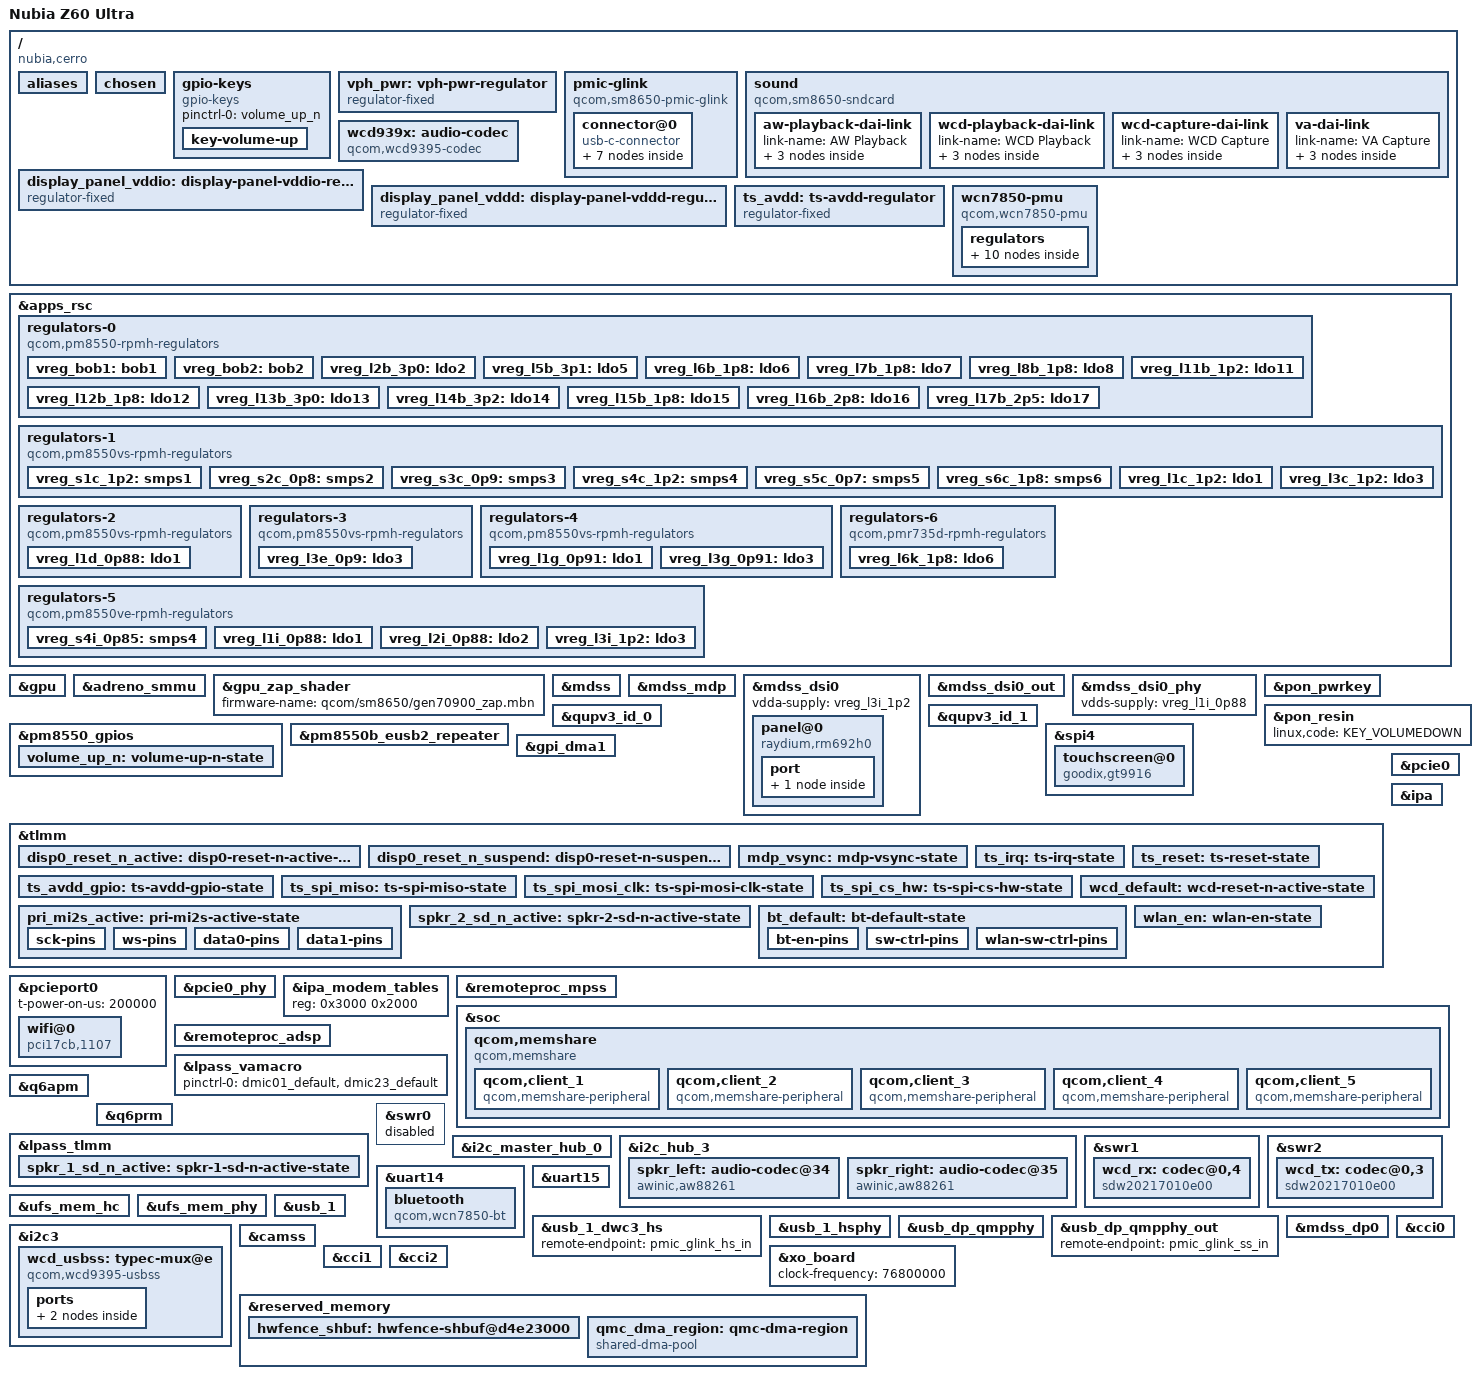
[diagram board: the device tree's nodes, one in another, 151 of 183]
// SPDX-License-Identifier: BSD-3-Clause
/*
 * Nubia Z60 Ultra (cerro / NX721J) mainline device tree.
 *
 * Provenance of the hardware facts:
 *   - Extracted offline from the stock firmware dump
 *     (see ../notes/cerro-hardware.md, ../downstream-dt/dts/dtbo_1.dts).
 *   - Cross-checked against the upstream SM8650 QRD reference board
 *     (arch/arm64/boot/dts/qcom/sm8650-qrd.dts), which carries the
 *     *identical* Visionox VTDR6130 panel and Goodix Berlin touch on
 *     spi4 (reset gpio161 / irq gpio162), UFS and USB wiring. cerro's
 *     display/touch/storage path is therefore a 1:1 match with the QRD.
 *
 * Scope: this is a first bring-up tree (console + storage + USB +
 * display + touch). Nubia-specific extras that are not needed to boot
 * pmOS to a display are intentionally omitted and listed at the bottom.
 *
 * Copyright (c) 2023, Linaro Limited (QRD reference)
 * Copyright (c) 2026, Nubia Z60U mainline port
 */

/dts-v1/;

#include <dt-bindings/gpio/gpio.h>
#include <dt-bindings/input/input.h>
#include <dt-bindings/interrupt-controller/irq.h>
#include <dt-bindings/regulator/qcom,rpmh-regulator.h>
#include <dt-bindings/sound/qcom,q6dsp-lpass-ports.h>
#include "sm8650.dtsi"
#include "pm8550.dtsi"
#include "pm8550b.dtsi"
#define PMK8550VE_SID 8
#include "pm8550ve.dtsi"
#include "pm8550vs.dtsi"
#include "pmk8550.dtsi"
#include "pmr735d_a.dtsi"

/* Phone SKU: hwfence is at 0xd4e23000 (not QRD 0xe6440000). */
/delete-node/ &hwfence_shbuf;

/ {
	model = "Nubia Z60 Ultra";
	compatible = "nubia,cerro", "qcom,sm8650";
	chassis-type = "handset";

	aliases {
		serial0 = &uart15;
		serial1 = &uart14;
	};

	chosen {
		stdout-path = "serial0:115200n8";
		/*
		 * Stock ABL leaves /proc/cmdline empty for our boot.img, so
		 * boot.img --cmdline is ineffective. Put bring-up args here.
		 */
		bootargs = "ignore_loglevel pd_ignore_unused clk_ignore_unused fw_devlink=on deferred_probe_timeout=60 console=tty0 fbcon=font:TER16x32 plymouth.enable=0 systemd.mask=plymouth-start.service systemd.mask=plymouth-quit.service systemd.mask=plymouth-quit-wait.service systemd.mask=plymouth-read-write.service systemd.mask=plymouth-reboot.service systemd.crash_reboot=1 panic=10 cerro_dtb=disp-on-oldsetup";
	};

	gpio-keys {
		compatible = "gpio-keys";

		pinctrl-0 = <&volume_up_n>;
		pinctrl-names = "default";

		key-volume-up {
			label = "Volume Up";
			linux,code = <KEY_VOLUMEUP>;
			gpios = <&pm8550_gpios 6 GPIO_ACTIVE_LOW>;
			debounce-interval = <15>;
			linux,can-disable;
			wakeup-source;
		};
	};

	vph_pwr: vph-pwr-regulator {
		compatible = "regulator-fixed";

		regulator-name = "vph_pwr";
		regulator-min-microvolt = <3700000>;
		regulator-max-microvolt = <3700000>;

		regulator-always-on;
		regulator-boot-on;
	};

	/*
	 * Battery + USB-C policy live on ADSP charger_pd (PMIC_RTR_ADSP_APPS).
	 * Without this node qcom_battmgr never probes: no capacity, no charge
	 * notifications. Graph endpoints match SM8650 MTP; orientation gpio is
	 * left unset until the Cerro CC pin is confirmed.
	 */
	pmic-glink {
		compatible = "qcom,sm8650-pmic-glink",
			     "qcom,sm8550-pmic-glink",
			     "qcom,pmic-glink";
		#address-cells = <1>;
		#size-cells = <0>;

		connector@0 {
			compatible = "usb-c-connector";
			reg = <0>;
			power-role = "dual";
			data-role = "dual";

			ports {
				#address-cells = <1>;
				#size-cells = <0>;

				port@0 {
					reg = <0>;
					pmic_glink_hs_in: endpoint {
						remote-endpoint = <&usb_1_dwc3_hs>;
					};
				};

				port@1 {
					reg = <1>;
					pmic_glink_ss_in: endpoint {
						remote-endpoint = <&usb_dp_qmpphy_out>;
					};
				};

				port@2 {
					reg = <2>;
					pmic_glink_sbu: endpoint {
						remote-endpoint = <&wcd_usbss_sbu_mux>;
					};
				};
			};
		};
	};

	/*
	 * s5fr/s5fu audio: WCD939x headset + 2× AW88261 smart PA (Cerro SKU).
	 * AOSP/stock: wsa-macro status=disabled; speakers on i2c_hub_3 @34/@35
	 * (chipid 0x2113). WSA SoundWire path retired after s5fq.
	 * s5fu: pri MI2S / i2s0 (gpio126–129) → AW88261; tplg from LEMANS-EVK
	 * (PRIMARY_MI2S_RX). Headset FE in old QRD tplg temporarily displaced.
	 */
	sound {
		compatible = "qcom,sm8650-sndcard", "qcom,sm8450-sndcard";
		model = "SM8650-CERRO";
		pinctrl-0 = <&pri_mi2s_active>;
		pinctrl-names = "default";
		/*
		 * s5fw: Audioreach MI2S needs q6prm IBIT vote before APM_CMD_SET_CFG.
		 * sc8280xp enables this on PRIMARY_MI2S startup (sm8250-style 1.536 MHz).
		 */
		clocks = <&q6prmcc LPASS_CLK_ID_PRI_MI2S_IBIT LPASS_CLK_ATTRIBUTE_COUPLE_NO>;
		clock-names = "pri_mi2s_ibit";
		audio-routing = "IN1_HPHL", "HPHL_OUT",
				"IN2_HPHR", "HPHR_OUT",
				"AMIC1", "MIC BIAS1",
				"AMIC2", "MIC BIAS2",
				"AMIC3", "MIC BIAS3",
				"AMIC4", "MIC BIAS3",
				"AMIC5", "MIC BIAS4",
				"TX SWR_INPUT0", "ADC1_OUTPUT",
				"TX SWR_INPUT1", "ADC2_OUTPUT",
				"TX SWR_INPUT2", "ADC3_OUTPUT",
				"TX SWR_INPUT3", "ADC4_OUTPUT";

		/* Speakers: AOSP pri_mi2s / i2s0 → 2× AW88261 (lemans-evk pattern) */
		aw-playback-dai-link {
			link-name = "AW Playback";

			cpu {
				sound-dai = <&q6apmbedai PRIMARY_MI2S_RX>;
			};

			codec {
				sound-dai = <&spkr_left>, <&spkr_right>;
			};

			platform {
				sound-dai = <&q6apm>;
			};
		};

		wcd-playback-dai-link {
			link-name = "WCD Playback";

			cpu {
				sound-dai = <&q6apmbedai RX_CODEC_DMA_RX_0>;
			};

			codec {
				sound-dai = <&wcd939x 0>, <&swr1 0>, <&lpass_rxmacro 0>;
			};

			platform {
				sound-dai = <&q6apm>;
			};
		};

		wcd-capture-dai-link {
			link-name = "WCD Capture";

			cpu {
				sound-dai = <&q6apmbedai TX_CODEC_DMA_TX_3>;
			};

			codec {
				sound-dai = <&wcd939x 1>, <&swr2 0>, <&lpass_txmacro 0>;
			};

			platform {
				sound-dai = <&q6apm>;
			};
		};

		/*
		 * Handset mics: stock LPASS DMIC on gpio6/7 and gpio8/9
		 * (dtbo dmic01/dmic23). va_macro is already bound; without
		 * this pinctrl the clocks stay unmuxed. Dedicated VA DMA so
		 * it does not steal WCD Capture's TX_CODEC_DMA_TX_3.
		 * Topology still has to grow a VA_CODEC_DMA_TX_0 backend
		 * before this link records; current CERRO tplg only feeds
		 * MultiMedia2 from TERTIARY_MI2S_TX.
		 */
		va-dai-link {
			link-name = "VA Capture";

			cpu {
				sound-dai = <&q6apmbedai VA_CODEC_DMA_TX_0>;
			};

			codec {
				sound-dai = <&lpass_vamacro 0>;
			};

			platform {
				sound-dai = <&q6apm>;
			};
		};
	};

	wcd939x: audio-codec {
		compatible = "qcom,wcd9395-codec", "qcom,wcd9390-codec";

		pinctrl-0 = <&wcd_default>;
		pinctrl-names = "default";

		qcom,micbias1-microvolt = <1800000>;
		qcom,micbias2-microvolt = <1800000>;
		qcom,micbias3-microvolt = <1800000>;
		qcom,micbias4-microvolt = <1800000>;
		qcom,mbhc-buttons-vthreshold-microvolt = <75000 150000 237000 500000 500000 500000 500000 500000>;
		qcom,mbhc-headset-vthreshold-microvolt = <1700000>;
		qcom,mbhc-headphone-vthreshold-microvolt = <50000>;
		qcom,rx-device = <&wcd_rx>;
		qcom,tx-device = <&wcd_tx>;

		reset-gpios = <&tlmm 107 GPIO_ACTIVE_LOW>;

		vdd-buck-supply = <&vreg_l15b_1p8>;
		vdd-rxtx-supply = <&vreg_l15b_1p8>;
		vdd-io-supply = <&vreg_l15b_1p8>;
		vdd-mic-bias-supply = <&vreg_bob1>;

		#sound-dai-cells = <1>;
	};

	/*
	 * Vendor zte-lcd-supply-cerro: GPIO load-switches for panel IO/core
	 * (display_panel_vddio / display_panel_vddd), boot-on in AOSP.
	 */
	display_panel_vddio: display-panel-vddio-regulator {
		compatible = "regulator-fixed";
		regulator-name = "display_panel_vddio";
		regulator-min-microvolt = <1800000>;
		regulator-max-microvolt = <1800000>;
		gpio = <&tlmm 14 GPIO_ACTIVE_HIGH>;
		enable-active-high;
		regulator-boot-on;
	};

	display_panel_vddd: display-panel-vddd-regulator {
		compatible = "regulator-fixed";
		regulator-name = "display_panel_vddd";
		regulator-min-microvolt = <1200000>;
		regulator-max-microvolt = <1200000>;
		gpio = <&tlmm 125 GPIO_ACTIVE_HIGH>;
		enable-active-high;
		regulator-boot-on;
	};

	/*
	 * s5dk / AOSP live (RM692H0 SKU): active touch is goodix,brl-d (9916R).
	 * AVDD is a GPIO load-switch on TLMM 28 — NOT L14B (L14B stays off on AOSP).
	 * gt9916S node exists in vendor DT but status=disabled on this panel SKU.
	 */
	ts_avdd: ts-avdd-regulator {
		compatible = "regulator-fixed";
		regulator-name = "ts_avdd";
		/* fixed-regulator requires min==max */
		regulator-min-microvolt = <3000000>;
		regulator-max-microvolt = <3000000>;
		gpio = <&tlmm 28 GPIO_ACTIVE_HIGH>;
		enable-active-high;
	};

	/*
	 * RF bisect: s5dr–s5du PASS (boot). s5du PCIe host probes but no
	 * link/devices — PERST/wake were on &pcie0; mainline puts them on
	 * &pcieport0 as reset-gpios/wake-gpios (sm8750-mtp / hamoa).
	 */
	wcn7850-pmu {
		compatible = "qcom,wcn7850-pmu";

		pinctrl-names = "default";
		pinctrl-0 = <&wlan_en>, <&bt_default>;

		wlan-enable-gpios = <&tlmm 16 GPIO_ACTIVE_HIGH>;
		bt-enable-gpios = <&tlmm 17 GPIO_ACTIVE_HIGH>;
		/* s5eh: AOSP cnss qcom,sw-ctrl-gpio / qcom,wlan-sw-ctrl-gpio */
		sw-ctrl-gpios = <&tlmm 18 GPIO_ACTIVE_HIGH>;
		wlan-sw-ctrl-gpios = <&tlmm 19 GPIO_ACTIVE_HIGH>;

		vdd-supply = <&vreg_s4i_0p85>;
		vddio-supply = <&vreg_l15b_1p8>;
		vddio1p2-supply = <&vreg_l3c_1p2>;
		vddaon-supply = <&vreg_s2c_0p8>;
		vdddig-supply = <&vreg_s3c_0p9>;
		vddrfa1p2-supply = <&vreg_s1c_1p2>;
		vddrfa1p8-supply = <&vreg_s6c_1p8>;

		clocks = <&rpmhcc RPMH_RF_CLK1>;

		regulators {
			vreg_pmu_rfa_cmn: ldo0 {
				regulator-name = "vreg_pmu_rfa_cmn";
			};

			vreg_pmu_aon_0p59: ldo1 {
				regulator-name = "vreg_pmu_aon_0p59";
			};

			vreg_pmu_wlcx_0p8: ldo2 {
				regulator-name = "vreg_pmu_wlcx_0p8";
			};

			vreg_pmu_wlmx_0p85: ldo3 {
				regulator-name = "vreg_pmu_wlmx_0p85";
			};

			vreg_pmu_btcmx_0p85: ldo4 {
				regulator-name = "vreg_pmu_btcmx_0p85";
			};

			vreg_pmu_rfa_0p8: ldo5 {
				regulator-name = "vreg_pmu_rfa_0p8";
			};

			vreg_pmu_rfa_1p2: ldo6 {
				regulator-name = "vreg_pmu_rfa_1p2";
			};

			vreg_pmu_rfa_1p8: ldo7 {
				regulator-name = "vreg_pmu_rfa_1p8";
			};

			vreg_pmu_pcie_0p9: ldo8 {
				regulator-name = "vreg_pmu_pcie_0p9";
			};

			vreg_pmu_pcie_1p8: ldo9 {
				regulator-name = "vreg_pmu_pcie_1p8";
			};
		};
	};
};

&apps_rsc {
	regulators-0 {
		compatible = "qcom,pm8550-rpmh-regulators";

		vdd-bob1-supply = <&vph_pwr>;
		vdd-bob2-supply = <&vph_pwr>;
		vdd-l2-l13-l14-supply = <&vreg_bob1>;
		vdd-l3-supply = <&vreg_s1c_1p2>;
		vdd-l5-l16-supply = <&vreg_bob1>;
		vdd-l6-l7-supply = <&vreg_bob1>;
		vdd-l8-l9-supply = <&vreg_bob1>;
		vdd-l11-supply = <&vreg_s1c_1p2>;
		vdd-l12-supply = <&vreg_s6c_1p8>;
		vdd-l15-supply = <&vreg_s6c_1p8>;
		vdd-l17-supply = <&vreg_bob2>;

		qcom,pmic-id = "b";

		vreg_bob1: bob1 {
			regulator-name = "vreg_bob1";
			regulator-min-microvolt = <3296000>;
			regulator-max-microvolt = <3960000>;
			regulator-initial-mode = <RPMH_REGULATOR_MODE_HPM>;
		};

		vreg_bob2: bob2 {
			regulator-name = "vreg_bob2";
			regulator-min-microvolt = <2720000>;
			regulator-max-microvolt = <3008000>;
			regulator-initial-mode = <RPMH_REGULATOR_MODE_HPM>;
		};

		vreg_l2b_3p0: ldo2 {
			regulator-name = "vreg_l2b_3p0";
			regulator-min-microvolt = <3008000>;
			regulator-max-microvolt = <3008000>;
			regulator-initial-mode = <RPMH_REGULATOR_MODE_HPM>;
			regulator-allow-set-load;
			regulator-allowed-modes = <RPMH_REGULATOR_MODE_LPM
						   RPMH_REGULATOR_MODE_HPM>;
		};

		vreg_l5b_3p1: ldo5 {
			regulator-name = "vreg_l5b_3p1";
			regulator-min-microvolt = <3104000>;
			regulator-max-microvolt = <3104000>;
			regulator-initial-mode = <RPMH_REGULATOR_MODE_HPM>;
			regulator-allow-set-load;
			regulator-allowed-modes = <RPMH_REGULATOR_MODE_LPM
						   RPMH_REGULATOR_MODE_HPM>;
		};

		vreg_l6b_1p8: ldo6 {
			regulator-name = "vreg_l6b_1p8";
			regulator-min-microvolt = <1800000>;
			regulator-max-microvolt = <3008000>;
			regulator-initial-mode = <RPMH_REGULATOR_MODE_HPM>;
			regulator-allow-set-load;
			regulator-allowed-modes = <RPMH_REGULATOR_MODE_LPM
						   RPMH_REGULATOR_MODE_HPM>;
		};

		vreg_l7b_1p8: ldo7 {
			regulator-name = "vreg_l7b_1p8";
			regulator-min-microvolt = <1800000>;
			regulator-max-microvolt = <3008000>;
			regulator-initial-mode = <RPMH_REGULATOR_MODE_HPM>;
		};

		vreg_l8b_1p8: ldo8 {
			regulator-name = "vreg_l8b_1p8";
			regulator-min-microvolt = <1800000>;
			regulator-max-microvolt = <3008000>;
			regulator-initial-mode = <RPMH_REGULATOR_MODE_HPM>;
			regulator-allow-set-load;
			regulator-allowed-modes = <RPMH_REGULATOR_MODE_LPM
						   RPMH_REGULATOR_MODE_HPM>;
		};

		vreg_l11b_1p2: ldo11 {
			regulator-name = "vreg_l11b_1p2";
			regulator-min-microvolt = <1200000>;
			regulator-max-microvolt = <1504000>;
			regulator-initial-mode = <RPMH_REGULATOR_MODE_HPM>;
			regulator-allow-set-load;
			regulator-allowed-modes = <RPMH_REGULATOR_MODE_LPM
						   RPMH_REGULATOR_MODE_HPM>;
		};

		vreg_l12b_1p8: ldo12 {
			regulator-name = "vreg_l12b_1p8";
			regulator-min-microvolt = <1800000>;
			regulator-max-microvolt = <1800000>;
			regulator-initial-mode = <RPMH_REGULATOR_MODE_HPM>;
			regulator-boot-on;
			regulator-always-on;
			regulator-allow-set-load;
			regulator-allowed-modes = <RPMH_REGULATOR_MODE_LPM
						   RPMH_REGULATOR_MODE_HPM>;
		};

		vreg_l13b_3p0: ldo13 {
			regulator-name = "vreg_l13b_3p0";
			regulator-min-microvolt = <3000000>;
			regulator-max-microvolt = <3000000>;
			regulator-initial-mode = <RPMH_REGULATOR_MODE_HPM>;
			regulator-allow-set-load;
			regulator-allowed-modes = <RPMH_REGULATOR_MODE_LPM
						   RPMH_REGULATOR_MODE_HPM>;
		};

		vreg_l14b_3p2: ldo14 {
			regulator-name = "vreg_l14b_3p2";
			regulator-min-microvolt = <3200000>;
			regulator-max-microvolt = <3200000>;
			regulator-initial-mode = <RPMH_REGULATOR_MODE_HPM>;
			/* s5de: drop always-on so touch can hard power-cycle AVDD */
			regulator-allow-set-load;
			regulator-allowed-modes = <RPMH_REGULATOR_MODE_LPM
						   RPMH_REGULATOR_MODE_HPM>;
		};

		vreg_l15b_1p8: ldo15 {
			regulator-name = "vreg_l15b_1p8";
			regulator-min-microvolt = <1800000>;
			regulator-max-microvolt = <1800000>;
			regulator-initial-mode = <RPMH_REGULATOR_MODE_HPM>;
			regulator-allow-set-load;
			regulator-allowed-modes = <RPMH_REGULATOR_MODE_LPM
						   RPMH_REGULATOR_MODE_HPM>;
		};

		vreg_l16b_2p8: ldo16 {
			regulator-name = "vreg_l16b_2p8";
			regulator-min-microvolt = <2800000>;
			regulator-max-microvolt = <2800000>;
			regulator-initial-mode = <RPMH_REGULATOR_MODE_HPM>;
			regulator-allow-set-load;
			regulator-allowed-modes = <RPMH_REGULATOR_MODE_LPM
						   RPMH_REGULATOR_MODE_HPM>;
		};

		vreg_l17b_2p5: ldo17 {
			regulator-name = "vreg_l17b_2p5";
			regulator-min-microvolt = <2504000>;
			regulator-max-microvolt = <2504000>;
			regulator-initial-mode = <RPMH_REGULATOR_MODE_HPM>;
			regulator-allow-set-load;
			regulator-allowed-modes = <RPMH_REGULATOR_MODE_LPM
						   RPMH_REGULATOR_MODE_HPM>;
		};
	};

	regulators-1 {
		compatible = "qcom,pm8550vs-rpmh-regulators";

		vdd-l1-supply = <&vreg_s1c_1p2>;
		vdd-l2-supply = <&vreg_s1c_1p2>;
		vdd-l3-supply = <&vreg_s1c_1p2>;
		vdd-s1-supply = <&vph_pwr>;
		vdd-s2-supply = <&vph_pwr>;
		vdd-s3-supply = <&vph_pwr>;
		vdd-s4-supply = <&vph_pwr>;
		vdd-s5-supply = <&vph_pwr>;
		vdd-s6-supply = <&vph_pwr>;

		qcom,pmic-id = "c";

		vreg_s1c_1p2: smps1 {
			regulator-name = "vreg_s1c_1p2";
			/* s5ea: AOSP cnss vdd-wlan-rfa2 1.316V (was 1.256) */
			regulator-min-microvolt = <1316000>;
			regulator-max-microvolt = <1348000>;
			regulator-initial-mode = <RPMH_REGULATOR_MODE_HPM>;
		};

		vreg_s2c_0p8: smps2 {
			regulator-name = "vreg_s2c_0p8";
			/* s5ea: AOSP cnss vdd-wlan-aon 0.976V (was 0.852) */
			regulator-min-microvolt = <976000>;
			regulator-max-microvolt = <1036000>;
			regulator-initial-mode = <RPMH_REGULATOR_MODE_HPM>;
		};

		vreg_s3c_0p9: smps3 {
			regulator-name = "vreg_s3c_0p9";
			regulator-min-microvolt = <976000>;
			regulator-max-microvolt = <1064000>;
			regulator-initial-mode = <RPMH_REGULATOR_MODE_HPM>;
		};

		vreg_s4c_1p2: smps4 {
			regulator-name = "vreg_s4c_1p2";
			regulator-min-microvolt = <1224000>;
			regulator-max-microvolt = <1280000>;
			regulator-initial-mode = <RPMH_REGULATOR_MODE_HPM>;
		};

		vreg_s5c_0p7: smps5 {
			regulator-name = "vreg_s5c_0p7";
			regulator-min-microvolt = <752000>;
			regulator-max-microvolt = <900000>;
			regulator-initial-mode = <RPMH_REGULATOR_MODE_HPM>;
		};

		vreg_s6c_1p8: smps6 {
			regulator-name = "vreg_s6c_1p8";
			regulator-min-microvolt = <1856000>;
			regulator-max-microvolt = <2000000>;
			regulator-initial-mode = <RPMH_REGULATOR_MODE_HPM>;
		};

		vreg_l1c_1p2: ldo1 {
			regulator-name = "vreg_l1c_1p2";
			regulator-min-microvolt = <1200000>;
			regulator-max-microvolt = <1200000>;
			regulator-initial-mode = <RPMH_REGULATOR_MODE_HPM>;
			regulator-allow-set-load;
			regulator-allowed-modes = <RPMH_REGULATOR_MODE_LPM
						   RPMH_REGULATOR_MODE_HPM>;
		};

		vreg_l3c_1p2: ldo3 {
			regulator-name = "vreg_l3c_1p2";
			regulator-min-microvolt = <1200000>;
			regulator-max-microvolt = <1200000>;
			regulator-initial-mode = <RPMH_REGULATOR_MODE_HPM>;
			regulator-allow-set-load;
			regulator-allowed-modes = <RPMH_REGULATOR_MODE_LPM
						   RPMH_REGULATOR_MODE_HPM>;
		};
	};

	regulators-2 {
		compatible = "qcom,pm8550vs-rpmh-regulators";

		vdd-l1-supply = <&vreg_s3c_0p9>;

		qcom,pmic-id = "d";

		vreg_l1d_0p88: ldo1 {
			regulator-name = "vreg_l1d_0p88";
			regulator-min-microvolt = <912000>;
			regulator-max-microvolt = <920000>;
			regulator-initial-mode = <RPMH_REGULATOR_MODE_HPM>;
			regulator-allow-set-load;
			regulator-allowed-modes = <RPMH_REGULATOR_MODE_LPM
						   RPMH_REGULATOR_MODE_HPM>;
		};
	};

	regulators-3 {
		compatible = "qcom,pm8550vs-rpmh-regulators";

		vdd-l3-supply = <&vreg_s3c_0p9>;

		qcom,pmic-id = "e";

		vreg_l3e_0p9: ldo3 {
			regulator-name = "vreg_l3e_0p9";
			regulator-min-microvolt = <880000>;
			regulator-max-microvolt = <920000>;
			regulator-initial-mode = <RPMH_REGULATOR_MODE_HPM>;
			regulator-allow-set-load;
			regulator-allowed-modes = <RPMH_REGULATOR_MODE_LPM
						   RPMH_REGULATOR_MODE_HPM>;
		};
	};

	regulators-4 {
		compatible = "qcom,pm8550vs-rpmh-regulators";

		vdd-l1-supply = <&vreg_s3c_0p9>;
		vdd-l3-supply = <&vreg_s3c_0p9>;

		qcom,pmic-id = "g";

		vreg_l1g_0p91: ldo1 {
			regulator-name = "vreg_l1g_0p91";
			regulator-min-microvolt = <912000>;
			regulator-max-microvolt = <920000>;
			regulator-initial-mode = <RPMH_REGULATOR_MODE_HPM>;
			regulator-allow-set-load;
			regulator-allowed-modes = <RPMH_REGULATOR_MODE_LPM
						   RPMH_REGULATOR_MODE_HPM>;
		};

		vreg_l3g_0p91: ldo3 {
			regulator-name = "vreg_l3g_0p91";
			regulator-min-microvolt = <880000>;
			regulator-max-microvolt = <912000>;
			regulator-initial-mode = <RPMH_REGULATOR_MODE_HPM>;
			regulator-allow-set-load;
			regulator-allowed-modes = <RPMH_REGULATOR_MODE_LPM
						   RPMH_REGULATOR_MODE_HPM>;
		};
	};

	regulators-5 {
		compatible = "qcom,pm8550ve-rpmh-regulators";

		vdd-l1-supply = <&vreg_s3c_0p9>;
		vdd-l2-supply = <&vreg_s3c_0p9>;
		vdd-l3-supply = <&vreg_s1c_1p2>;
		vdd-s4-supply = <&vph_pwr>;

		qcom,pmic-id = "i";

		vreg_s4i_0p85: smps4 {
			regulator-name = "vreg_s4i_0p85";
			/* s5ea: AOSP cnss vdd-wlan ~0.94V (was 0.852) */
			regulator-min-microvolt = <940000>;
			regulator-max-microvolt = <1004000>;
			regulator-initial-mode = <RPMH_REGULATOR_MODE_HPM>;
		};

		vreg_l1i_0p88: ldo1 {
			regulator-name = "vreg_l1i_0p88";
			regulator-min-microvolt = <880000>;
			regulator-max-microvolt = <912000>;
			regulator-initial-mode = <RPMH_REGULATOR_MODE_HPM>;
			regulator-allow-set-load;
			regulator-allowed-modes = <RPMH_REGULATOR_MODE_LPM
						   RPMH_REGULATOR_MODE_HPM>;
		};

		vreg_l2i_0p88: ldo2 {
			regulator-name = "vreg_l2i_0p88";
			regulator-min-microvolt = <880000>;
			regulator-max-microvolt = <912000>;
			regulator-initial-mode = <RPMH_REGULATOR_MODE_HPM>;
			regulator-allow-set-load;
			regulator-allowed-modes = <RPMH_REGULATOR_MODE_LPM
						   RPMH_REGULATOR_MODE_HPM>;
		};

		vreg_l3i_1p2: ldo3 {
			regulator-name = "vreg_l3i_1p2";
			regulator-min-microvolt = <1200000>;
			regulator-max-microvolt = <1200000>;
			regulator-initial-mode = <RPMH_REGULATOR_MODE_HPM>;
			regulator-allow-set-load;
			regulator-allowed-modes = <RPMH_REGULATOR_MODE_LPM
						   RPMH_REGULATOR_MODE_HPM>;
		};
	};

	/*
	 * s5ed: AOSP cnss-kiwi / bt_kiwi share vdd-wlan-ant-share = L6K
	 * (pmr735d ldo6 @ ~1.8V). Mainline had no pmr735d regulators node;
	 * always-on until we have a consumer property on wcn7850-pmu.
	 */
	regulators-6 {
		compatible = "qcom,pmr735d-rpmh-regulators";
		qcom,pmic-id = "k";

		vdd-l6-supply = <&vreg_bob1>;

		vreg_l6k_1p8: ldo6 {
			regulator-name = "vreg_l6k_1p8";
			/* AOSP: min 1.776V max 1.86V, init 1.8V */
			regulator-min-microvolt = <1800000>;
			regulator-max-microvolt = <1800000>;
			regulator-initial-mode = <RPMH_REGULATOR_MODE_HPM>;
			regulator-always-on;
			regulator-boot-on;
			regulator-allow-set-load;
			regulator-allowed-modes = <RPMH_REGULATOR_MODE_LPM
						   RPMH_REGULATOR_MODE_HPM>;
		};
	};
};

&gpu {
	/*
	 * s5et: enable Adreno a750 + GMU. Needs uncompressed FW on rootfs
	 * (CONFIG_FW_LOADER_COMPRESS=n): qcom/sm8650/gen70900_zap.mbn,
	 * qcom/gmu_gen70900.bin, qcom/gen70900_{sqe,aqe}.fw.
	 * Earlier bring-up disabled this to avoid mdss -ETIMEDOUT without FW.
	 */
	status = "okay";
};

&adreno_smmu {
	status = "okay";
};

&gpu_zap_shader {
	/*
	 * Must be stock vendor zap (notes/firmware-gpu-sm8650/).
	 * linux-firmware generic SM8650 zap → SCM -EINVAL (s5et).
	 */
	firmware-name = "qcom/sm8650/gen70900_zap.mbn";
};

&mdss {
	/* Parent OK with msm-mdss bound (mdss-shell PASS). */
	status = "okay";
};

&mdss_mdp {
	/*
	 * s2-noasgn PASS (got 5 clks). Hang was assigned-clocks on
	 * clk_bulk_get; keep PD/OPP/assigned-clocks peeled.
	 */
	status = "okay";
	/delete-property/ power-domains;
	/delete-property/ operating-points-v2;
	/delete-property/ assigned-clocks;
	/delete-property/ assigned-clock-rates;
};

&mdss_dsi0 {
	vdda-supply = <&vreg_l3i_1p2>;

	/*
	 * Panel: Raydium RM692H0 (cerro BF068). Keep PD/OPP peeled for now;
	 * restore assigned-clocks (s5ad: link clk set_rate -22 without them).
	 */
	status = "okay";
	/delete-property/ power-domains;
	/delete-property/ operating-points-v2;

	panel@0 {
		compatible = "raydium,rm692h0", "zte,bf068-rm692h0";
		reg = <0>;

		reset-gpios = <&tlmm 133 GPIO_ACTIVE_LOW>;
		/* CMD mode TE (vendor te-pin-select / gpio86 mdp_vsync). */
		te-gpios = <&tlmm 86 GPIO_ACTIVE_HIGH>;

		/* Vendor: vddiocerro/vdddcerro GPIO + vdd/vci LDOs */
		vddio-supply = <&display_panel_vddio>;
		vddd-supply = <&display_panel_vddd>;
		vdd-supply = <&vreg_l11b_1p2>;
		vci-supply = <&vreg_l13b_3p0>;

		pinctrl-0 = <&disp0_reset_n_active>, <&mdp_vsync>;
		pinctrl-1 = <&disp0_reset_n_suspend>, <&mdp_vsync>;
		pinctrl-names = "default", "sleep";

		port {
			panel0_in: endpoint {
				remote-endpoint = <&mdss_dsi0_out>;
			};
		};
	};
};

&mdss_dsi0_out {
	remote-endpoint = <&panel0_in>;
	data-lanes = <0 1 2 3>;
	/*
	 * s5bo: force GPIO TE. Livetree uses prefer_builtin_dtb → must refresh
	 * arch/arm64/kernel/sm8650-nubia-cerro.dtb (not only boot/dts or dtb-id).
	 */
	qcom,te-source = "mdp_vsync_p";
};

&mdss_dsi0_phy {
	vdds-supply = <&vreg_l1i_0p88>;

	status = "okay";
};

&pon_pwrkey {
	status = "okay";
};

&pon_resin {
	linux,code = <KEY_VOLUMEDOWN>;

	status = "okay";
};

&pm8550_gpios {
	volume_up_n: volume-up-n-state {
		pins = "gpio6";
		function = "normal";
		bias-pull-up;
		input-enable;
		power-source = <1>;
	};
};

&pm8550b_eusb2_repeater {
	vdd18-supply = <&vreg_l15b_1p8>;
	vdd3-supply = <&vreg_l5b_3p1>;
};

&qupv3_id_0 {
	status = "okay";
};

/* QRD enables both wraps; match for SPI/touch bring-up. */
&qupv3_id_1 {
	status = "okay";
};

&spi4 {
	status = "okay";

	/*
	 * s5di: QRD-style native HW CS (gpio51 = qup1_se4), keep s5dg MISO
	 * pull-up so float reads 0xff. (s5dg used cs-gpios; still mute.)
	 */
	pinctrl-0 = <&ts_spi_miso>, <&ts_spi_mosi_clk>, <&ts_spi_cs_hw>;
	pinctrl-names = "default";

	touchscreen@0 {
		compatible = "goodix,gt9916";
		reg = <0>;

		interrupt-parent = <&tlmm>;
		/*
		 * Vendor irq-flags=0x02 (EDGE_FALLING). QRD uses LEVEL_LOW;
		 * keep EDGE_FALLING to match Cerro DTBO.
		 */
		interrupts = <162 IRQ_TYPE_EDGE_FALLING>;

		/*
		 * Vendor requests reset with GPIOF_OUT_INIT_LOW and later
		 * drives gpio=1 to run — physical HIGH = release.
		 * That matches GPIO_ACTIVE_LOW (assert=LOW).
		 * (s5db ACTIVE_HIGH also failed confirm.)
		 */
		reset-gpios = <&tlmm 161 GPIO_ACTIVE_LOW>;
		/* s5dj: drive during reset; same pin as interrupts */
		irq-gpios = <&tlmm 162 GPIO_ACTIVE_HIGH>;

		/* s5dk: brl-d AVDD=gpio28 load-switch; IOVDD=L12B (AOSP pm_humu_l12) */
		avdd-supply = <&ts_avdd>;
		vddio-supply = <&vreg_l12b_1p8>;

		/* Live brl-d node: 20MHz (gt9916S disabled path was 1MHz) */
		spi-max-frequency = <20000000>;

		/*
		 * AOSP brl-d: goodix,panel-max-x/y = 0x45c0 / 0x9b00
		 * (= 16 × 1116 × 2480). IC reports in that space; s5dl used
		 * 1116×2480 so ABS max was too small (raw Y saw >2479).
		 */
		touchscreen-size-x = <17856>;
		touchscreen-size-y = <39680>;

		pinctrl-0 = <&ts_irq>, <&ts_reset>, <&ts_avdd_gpio>;
		pinctrl-names = "default";
	};
};

/* SPI4 touch needs GPI DMA (geni_spi deferred without it). */
&gpi_dma1 {
	status = "okay";
};

&tlmm {
	disp0_reset_n_active: disp0-reset-n-active-state {
		pins = "gpio133";
		function = "gpio";
		drive-strength = <8>;
		bias-disable;
	};

	disp0_reset_n_suspend: disp0-reset-n-suspend-state {
		pins = "gpio133";
		function = "gpio";
		drive-strength = <2>;
		bias-pull-down;
	};

	mdp_vsync: mdp-vsync-state {
		pins = "gpio86";
		function = "mdp_vsync";
		drive-strength = <2>;
		bias-pull-down;
	};

	/* irq=gpio162, reset=gpio161 (was swapped; broke Goodix probe) */
	ts_irq: ts-irq-state {
		pins = "gpio162";
		function = "gpio";
		drive-strength = <8>;
		bias-pull-up;
		output-disable;
	};

	ts_reset: ts-reset-state {
		pins = "gpio161";
		function = "gpio";
		drive-strength = <8>;
		bias-pull-up;
	};

	/* s5dk: mux AVDD enable as GPIO (level driven by regulator-fixed) */
	ts_avdd_gpio: ts-avdd-gpio-state {
		pins = "gpio28";
		function = "gpio";
		drive-strength = <8>;
		bias-disable;
	};

	/* s5dg/s5di: SPI4 MISO pull-up (float→0xff); MOSI/CLK no pull */
	ts_spi_miso: ts-spi-miso-state {
		pins = "gpio48";
		function = "qup1_se4";
		drive-strength = <8>;
		bias-pull-up;
	};

	ts_spi_mosi_clk: ts-spi-mosi-clk-state {
		pins = "gpio49", "gpio50";
		function = "qup1_se4";
		drive-strength = <8>;
		bias-disable;
	};

	/* s5di: native CS (was ts_spi_cs_gpio in s5dg) */
	ts_spi_cs_hw: ts-spi-cs-hw-state {
		pins = "gpio51";
		function = "qup1_se4";
		drive-strength = <8>;
		bias-disable;
	};

	/* s5ex: WCD939x reset (vb_04 / QRD gpio107) */
	wcd_default: wcd-reset-n-active-state {
		pins = "gpio107";
		function = "gpio";
		drive-strength = <16>;
		bias-disable;
		output-low;
	};

	/*
	 * s5fu: AOSP/stock pri_mi2s / i2s0 (vb_03 aux0_pcm_*).
	 * gpio126 sck, 129 ws, 127 data0, 128 data1 — drive 8 like vendor active.
	 */
	pri_mi2s_active: pri-mi2s-active-state {
		sck-pins {
			pins = "gpio126";
			function = "i2s0_sck";
			drive-strength = <8>;
			bias-disable;
			output-high;
		};

		ws-pins {
			pins = "gpio129";
			function = "i2s0_ws";
			drive-strength = <8>;
			bias-disable;
			output-high;
		};

		data0-pins {
			pins = "gpio127";
			function = "i2s0_data0";
			drive-strength = <8>;
			bias-disable;
		};

		data1-pins {
			pins = "gpio128";
			function = "i2s0_data1";
			drive-strength = <8>;
			bias-disable;
		};
	};

	/* s5fk: match downstream aud_active (output-high). SD_N is ACTIVE_LOW
	 * in powerdown-gpios; physical HIGH = out of shutdown. QRD mainline
	 * uses output-low + driver deassert; on cerro WSA stayed UNATTACHED
	 * with left LPASS21 stuck low — try board-faithful pinctrl first.
	 */
	spkr_2_sd_n_active: spkr-2-sd-n-active-state {
		pins = "gpio77";
		function = "gpio";
		drive-strength = <16>;
		bias-disable;
		output-high;
	};

	/* s5fq: drop spkr_2_sd_n_hog — restore powerdown-gpios consumer */

	bt_default: bt-default-state {
		bt-en-pins {
			pins = "gpio17";
			function = "gpio";
			drive-strength = <16>;
			bias-disable;
		};

		/* s5eh: drive high via pwrseq; drop pull-down that left pins low when undriven */
		sw-ctrl-pins {
			pins = "gpio18";
			function = "gpio";
			drive-strength = <8>;
			bias-disable;
		};

		/* cerro dtbo: qcom,wlan-sw-ctrl-gpio = tlmm 19 (QRD has only 18) */
		wlan-sw-ctrl-pins {
			pins = "gpio19";
			function = "gpio";
			drive-strength = <8>;
			bias-disable;
		};
	};

	wlan_en: wlan-en-state {
		pins = "gpio16";
		function = "gpio";
		drive-strength = <8>;
		bias-pull-down;
	};
};

/*
 * s5dx: PERST/wake on &pcie0 like sm8650-qrd / ayaneo (s5dv put them on
 * pcieport0; gpio94 stayed input / WLAN_EN never asserted).
 */
&pcie0 {
	wake-gpios = <&tlmm 96 GPIO_ACTIVE_HIGH>;
	perst-gpios = <&tlmm 94 GPIO_ACTIVE_LOW>;

	pinctrl-0 = <&pcie0_default_state>;
	pinctrl-names = "default";

	status = "okay";
};

&pcieport0 {
	/* s5eb: match QRD (drop Gen1/lane overrides; s5ea still DNF) */
	t-power-on-us = <200000>;

	wifi@0 {
		compatible = "pci17cb,1107";
		reg = <0x10000 0x0 0x0 0x0 0x0>;

		vddrfacmn-supply = <&vreg_pmu_rfa_cmn>;
		vddaon-supply = <&vreg_pmu_aon_0p59>;
		vddwlcx-supply = <&vreg_pmu_wlcx_0p8>;
		vddwlmx-supply = <&vreg_pmu_wlmx_0p85>;
		vddrfa0p8-supply = <&vreg_pmu_rfa_0p8>;
		vddrfa1p2-supply = <&vreg_pmu_rfa_1p2>;
		vddrfa1p8-supply = <&vreg_pmu_rfa_1p8>;
		vddpcie0p9-supply = <&vreg_pmu_pcie_0p9>;
		vddpcie1p8-supply = <&vreg_pmu_pcie_1p8>;
	};
};

&pcie0_phy {
	vdda-phy-supply = <&vreg_l1i_0p88>;
	vdda-pll-supply = <&vreg_l3i_1p2>;

	status = "okay";
};

/*
 * Cellular candidate 1: use the upstream SM8650 4 MiB rmtfs reservation at
 * 0xd7c00000 (the Cerro stock map leaves the range before tz@d8000000 free).
 * Userspace starts this auto_boot=false remoteproc only after publishing the
 * read-only raw-partition RMTFS service.
 */
&ipa {
	qcom,gsi-loader = "self";
	memory-region = <&ipa_fw_mem>;
	firmware-name = "qcom/sm8650/ipa_fws.mdt";

	status = "okay";
};

/*
 * Stock pineapple-ipa.dtbo adds an identity mapping 0x14683000..0x14684fff
 * to the IPA AP SMMU context (SID 0x4a0).  The IPA driver only identity-maps
 * this DT sram window, so the mainline modem-tables@8000 default left the
 * stock-required IOVA 0x14684080 unmapped: every boot produced the same
 * apps-SMMU translation fault (FSR 0x402, cb5) followed by whole-device
 * hard resets.  Moving the window to the stock offset 0x3000 eliminates the
 * fault and the reset loop (stability-ipa-imem-c1, verified 2026-08-19).
 */
&ipa_modem_tables {
	reg = <0x3000 0x2000>;
};

&remoteproc_mpss {
	firmware-name = "qcom/sm8650/modem.mdt",
			"qcom/sm8650/modem_dtb.mdt";

	status = "okay";
};

/*
 * Cerro stock MPSS queries Dynamic Heap Memory Sharing client 1 and requests
 * exactly 5 MiB before IPA/DMS initialization.  Keep all five stock clients;
 * the service driver is loaded before qcom_q6v5_pas starts the modem.
 */
&soc {
	qcom,memshare {
		compatible = "qcom,memshare";

		qcom,client_1 {
			compatible = "qcom,memshare-peripheral";
			qcom,peripheral-size = <0>;
			qcom,client-id = <0>;
			qcom,allocate-boot-time;
			label = "modem";
		};

		qcom,client_2 {
			compatible = "qcom,memshare-peripheral";
			qcom,peripheral-size = <0>;
			qcom,client-id = <2>;
			label = "modem";
		};

		qcom,client_3 {
			compatible = "qcom,memshare-peripheral";
			qcom,peripheral-size = <0x00500000>;
			qcom,client-id = <1>;
			qcom,allocate-on-request;
			label = "modem";
		};

		qcom,client_4 {
			compatible = "qcom,memshare-peripheral";
			qcom,peripheral-size = <0x01000000>;
			qcom,client-id = <5>;
			qcom,allocate-on-request;
			qcom,shared;
			memory-region = <&qmc_dma_region>;
			label = "modem";
		};

		qcom,client_5 {
			compatible = "qcom,memshare-peripheral";
			qcom,peripheral-size = <0x00400000>;
			qcom,client-id = <6>;
			qcom,allocate-on-request;
			qcom,shared;
			label = "modem";
		};
	};
};

/* s5fc: ADSP okay but driver auto_boot=false (see qcom_q6v5_pas cerro data).
 * cerro-audio stages modem_a fw then echo start. s5fa auto-boot hung pre-getty.
 */
&remoteproc_adsp {
	firmware-name = "qcom/sm8650/adsp.mdt",
			"qcom/sm8650/adsp_dtb.mdt";

	status = "okay";
};

/*
 * s5ff: PDR never publishes msm/adsp/audio_pd → aprbus stays empty → no q6prm
 * clocks → va_macro deferred forever. Skip PD gate for bringup (services still
 * talk to ADSP over GPR once registered).
 */
&lpass_vamacro {
	pinctrl-0 = <&dmic01_default>, <&dmic23_default>;
	pinctrl-names = "default";
};

&q6apm {
	/delete-property/ qcom,protection-domain;
};

&q6prm {
	/delete-property/ qcom,protection-domain;
};

&lpass_tlmm {
	/* s5fk: downstream spkr_02_sd_n_active = output-high on LPASS gpio21 */
	spkr_1_sd_n_active: spkr-1-sd-n-active-state {
		pins = "gpio21";
		function = "gpio";
		drive-strength = <16>;
		bias-disable;
		output-high;
	};

	/* s5fq: drop spkr_1_sd_n_hog — wsa884x powerdown-gpios owns the line */
};

/*
 * s5fr/s5fs: Cerro has no WSA884x on swr0 (AOSP/stock wsa-macro disabled).
 * Speakers are AW88261 on &i2c_hub_3.
 */
&swr0 {
	status = "disabled";
};

/*
 * s5fs: parent hub must be okay or i2c@98c000 never probes (s5fr lesson:
 * DT had aw88261 nodes + module loaded, but /sys/bus/i2c/devices empty).
 */
&i2c_master_hub_0 {
	status = "okay";
};

/*
 * AOSP: qupv3_hub_i2c3 @98c000, aw882xx_smartpa@34/@35, chipid 0x2113.
 * sound-channel: @34=1 @35=0. Firmware: notes/firmware-aw882xx/aw882xx_acf.bin
 */
&i2c_hub_3 {
	status = "okay";

	spkr_left: audio-codec@34 {
		compatible = "awinic,aw88261";
		reg = <0x34>;
		#sound-dai-cells = <0>;
		sound-name-prefix = "SpkrLeft";
		dvdd-supply = <&vreg_l15b_1p8>;
		awinic,audio-channel = <1>;
		firmware-name = "aw882xx_acf.bin";
	};

	spkr_right: audio-codec@35 {
		compatible = "awinic,aw88261";
		reg = <0x35>;
		#sound-dai-cells = <0>;
		sound-name-prefix = "SpkrRight";
		dvdd-supply = <&vreg_l15b_1p8>;
		awinic,audio-channel = <0>;
		firmware-name = "aw882xx_acf.bin";
	};
};

&swr1 {
	status = "okay";

	wcd_rx: codec@0,4 {
		compatible = "sdw20217010e00";
		reg = <0 4>;
		qcom,rx-port-mapping = <1 2 3 4 5 9>;
	};
};

&swr2 {
	status = "okay";

	wcd_tx: codec@0,3 {
		compatible = "sdw20217010e00";
		reg = <0 3>;
		qcom,tx-port-mapping = <2 2 3 4>;
	};
};

/* s5du: keep BT; PCIe enabled above */
&uart14 {
	status = "okay";

	bluetooth {
		compatible = "qcom,wcn7850-bt";

		vddrfacmn-supply = <&vreg_pmu_rfa_cmn>;
		vddaon-supply = <&vreg_pmu_aon_0p59>;
		vddwlcx-supply = <&vreg_pmu_wlcx_0p8>;
		vddwlmx-supply = <&vreg_pmu_wlmx_0p85>;
		vddrfa0p8-supply = <&vreg_pmu_rfa_0p8>;
		vddrfa1p2-supply = <&vreg_pmu_rfa_1p2>;
		vddrfa1p8-supply = <&vreg_pmu_rfa_1p8>;

		max-speed = <3200000>;
		/* Little-endian. Displays as 02:00:95:0B:4D:FF. */
		local-bd-address = [ ff 4d 0b 95 00 02 ];
	};
};

&uart15 {
	status = "okay";
};

&ufs_mem_hc {
	reset-gpios = <&tlmm 210 GPIO_ACTIVE_LOW>;

	vcc-supply = <&vreg_l17b_2p5>;
	vcc-max-microamp = <1300000>;
	vccq-supply = <&vreg_l1c_1p2>;
	vccq-max-microamp = <1200000>;

	status = "okay";
};

&ufs_mem_phy {
	vdda-phy-supply = <&vreg_l1d_0p88>;
	vdda-pll-supply = <&vreg_l3i_1p2>;

	status = "okay";
};

&usb_1 {
	/* Path A bring-up used peripheral-only; OTG needs dual-role + role switch
	 * (SM8650 HDK/MTP). pmic-glink connector already data-role/power-role dual. */
	dr_mode = "otg";
	usb-role-switch;

	status = "okay";
};

&usb_1_dwc3_hs {
	remote-endpoint = <&pmic_glink_hs_in>;
};

&usb_1_hsphy {
	vdd-supply = <&vreg_l1i_0p88>;
	vdda12-supply = <&vreg_l3i_1p2>;

	phys = <&pm8550b_eusb2_repeater>;

	status = "okay";
};

&usb_dp_qmpphy {
	vdda-phy-supply = <&vreg_l3i_1p2>;
	vdda-pll-supply = <&vreg_l3g_0p91>;

	status = "okay";
};

&usb_dp_qmpphy_out {
	remote-endpoint = <&pmic_glink_ss_in>;
};

/* Aurora Cerro routes DP AUX through WCD939x USBSS at a8c000:0e/L15B.
 * No reset GPIO is described for this board (do not copy QRD GPIO152).
 * The headset graph is a separate audio experiment; this is DP SBU only.
 */
&i2c3 {
	status = "okay";

	wcd_usbss: typec-mux@e {
		compatible = "qcom,wcd9395-usbss", "qcom,wcd9390-usbss";
		reg = <0xe>;
		vdd-supply = <&vreg_l15b_1p8>;
		mode-switch;
		orientation-switch;

		ports {
			#address-cells = <1>;
			#size-cells = <0>;

			port@0 {
				reg = <0>;
				wcd_usbss_sbu_mux: endpoint {
					remote-endpoint = <&pmic_glink_sbu>;
				};
			};
		};
	};
};

&mdss_dp0 {
	status = "okay";
};

/*
 * Camera SoC bring-up (2026-10-23): enable CAMSS + CCI only.
 * CSIPHY supplies: Android/QRD share ~0.9V/1.2V rails (cerro L2I/L3I).
 * Wire all three supply groups so every CSIPHY can regulator_bulk_get.
 * Sensors (imx800/…) are a later single-variable DT+driver step.
 */
&camss {
	vdd-csiphy01-0p9-supply = <&vreg_l2i_0p88>;
	vdd-csiphy01-1p2-supply = <&vreg_l3i_1p2>;
	vdd-csiphy24-0p9-supply = <&vreg_l2i_0p88>;
	vdd-csiphy24-1p2-supply = <&vreg_l3i_1p2>;
	vdd-csiphy35-0p9-supply = <&vreg_l2i_0p88>;
	vdd-csiphy35-1p2-supply = <&vreg_l3i_1p2>;
	status = "okay";
};

&cci0 {
	status = "okay";
};

&cci1 {
	status = "okay";
};

&cci2 {
	status = "okay";
};

&xo_board {
	clock-frequency = <76800000>;
};

&reserved_memory {
	hwfence_shbuf: hwfence-shbuf@d4e23000 {
		reg = <0 0xd4e23000 0 0x2dd000>;
		no-map;
	};

	qmc_dma_region: qmc-dma-region {
		compatible = "shared-dma-pool";
		reusable;
		size = <0 0x01000000>;
		alignment = <0 0x00400000>;
		alloc-ranges = <0 0 0 0xffffffff>;
	};

	/* s5dr: drop cnss CMA until RF subset boots */
};

/*
 * TODO (post-bring-up, cerro-specific, extracted downstream data in
 * ../notes/cerro-hardware.md and ../downstream-dt/dts/dtbo_1.dts):
 *   - WiFi/BT DTS (s5dn): WCN7850 via PCIe0+UART14, QRD-compatible wiring
 *     verified against downstream cnss-kiwi / pcie0. Still need modules +
 *     ath12k/qca firmware on rootfs; modem needs vendor MBA/modem + rmtfs.
 *   - NFC: st21nfc@08 (I2C) + st54spi (SPI secure element).
 *   - Audio (s5fr): WCD939x headset; 2× AW88261 on i2c_hub_3 (not WSA884x).
 *   - Haptics: awinic haptic_hv@5A (I2C).
 *   - Game shoulder-key slider: gpio_keys_nubia (game_sw_on/off) - need
 *     the exact TLMM pins from a fuller downstream dump.
 *   - Fingerprint (goodix, SPI, pwr gpio TLMM93): no mainline driver.
 */
